AUTOSAR XML (schema 4-0-3)
package /ComponentTypes
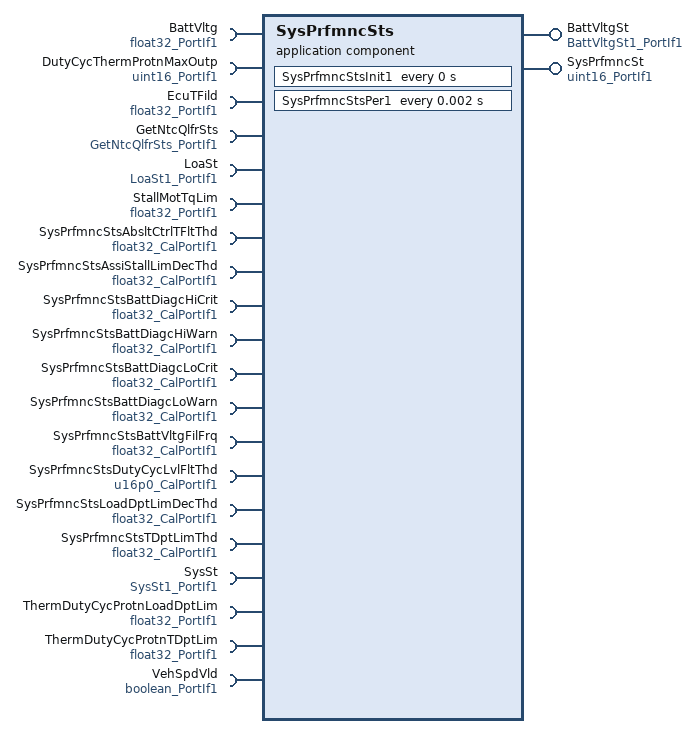
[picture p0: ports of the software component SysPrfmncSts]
  application sw component type SysPrfmncSts
    provide port BattVltgSt: nonqueued-sender-com-spec{data-element=Val, init-value=0}, provided-interface=BattVltgSt1_PortIf1
    provide port SysPrfmncSt: nonqueued-sender-com-spec{data-element=Val, init-value=0}, provided-interface=uint16_PortIf1
    20 x require port:
      BattVltg: nonqueued-receiver-com-spec{data-element=Val, filter=data-filter-type=ALWAYS, init-value=5}, required-interface=float32_PortIf1
      DutyCycThermProtnMaxOutp: nonqueued-receiver-com-spec{data-element=Val, filter=data-filter-type=ALWAYS, init-value=0}, required-interface=uint16_PortIf1
      EcuTFild: nonqueued-receiver-com-spec{data-element=Val, filter=data-filter-type=ALWAYS, init-value=25}, required-interface=float32_PortIf1
      GetNtcQlfrSts: client-com-spec=Oper, required-interface=GetNtcQlfrSts_PortIf1
      LoaSt: nonqueued-receiver-com-spec{data-element=Val, filter=data-filter-type=ALWAYS, init-value=0}, required-interface=LoaSt1_PortIf1
      StallMotTqLim: nonqueued-receiver-com-spec{data-element=Val, filter=data-filter-type=ALWAYS, init-value=8.8}, required-interface=float32_PortIf1
      SysPrfmncStsAbsltCtrlTFltThd: parameter-require-com-spec{init-value=91, parameter=Val}, required-interface=float32_CalPortIf1
      SysPrfmncStsAssiStallLimDecThd: parameter-require-com-spec{init-value=8.8, parameter=Val}, required-interface=float32_CalPortIf1
      SysPrfmncStsBattDiagcHiCrit: parameter-require-com-spec{init-value=18, parameter=Val}, required-interface=float32_CalPortIf1
      SysPrfmncStsBattDiagcHiWarn: parameter-require-com-spec{init-value=17.5, parameter=Val}, required-interface=float32_CalPortIf1
      SysPrfmncStsBattDiagcLoCrit: parameter-require-com-spec{init-value=9, parameter=Val}, required-interface=float32_CalPortIf1
      SysPrfmncStsBattDiagcLoWarn: parameter-require-com-spec{init-value=11.3, parameter=Val}, required-interface=float32_CalPortIf1
      SysPrfmncStsBattVltgFilFrq: parameter-require-com-spec{init-value=10, parameter=Val}, required-interface=float32_CalPortIf1
      SysPrfmncStsDutyCycLvlFltThd: parameter-require-com-spec{init-value=70, parameter=Val}, required-interface=u16p0_CalPortIf1
      SysPrfmncStsLoadDptLimDecThd: parameter-require-com-spec{init-value=8.8, parameter=Val}, required-interface=float32_CalPortIf1
      SysPrfmncStsTDptLimThd: parameter-require-com-spec{init-value=8.8, parameter=Val}, required-interface=float32_CalPortIf1
      SysSt: nonqueued-receiver-com-spec{data-element=Val, filter=data-filter-type=ALWAYS, init-value=3}, required-interface=SysSt1_PortIf1
      ThermDutyCycProtnLoadDptLim: nonqueued-receiver-com-spec{data-element=Val, filter=data-filter-type=ALWAYS, init-value=8.8}, required-interface=float32_PortIf1
      ThermDutyCycProtnTDptLim: nonqueued-receiver-com-spec{data-element=Val, filter=data-filter-type=ALWAYS, init-value=8.8}, required-interface=float32_PortIf1
      VehSpdVld: nonqueued-receiver-com-spec{data-element=Logl, filter=data-filter-type=ALWAYS, init-value=0}, required-interface=boolean_PortIf1
    behavior SysPrfmncSts_InternalBehavior
      ar-typed-per-instance-memorys:
        data BattVltgLpFil: sw-calibration-access=READ-ONLY, type=FilLpRec1
      timing event SysPrfmncSts_InitEvent: start-on-event=SysPrfmncStsInit1, period=0
      timing event TMT_SysPrfmncStsPer1: start-on-event=SysPrfmncStsPer1, period=0.002
      runnable SysPrfmncStsInit1
      runnable SysPrfmncStsPer1
        data-receive-point-by-arguments:
          9 x access:
            REC_BattVltg_Val: accessed-variable=BattVltg.Val
            REC_DutyCycThermProtnMaxOutp_Val: accessed-variable=DutyCycThermProtnMaxOutp.Val
            REC_EcuTFild_Val: accessed-variable=EcuTFild.Val
            REC_LoaSt_Val: accessed-variable=LoaSt.Val
            REC_StallMotTqLim_Val: accessed-variable=StallMotTqLim.Val
            REC_SysSt_Val: accessed-variable=SysSt.Val
            REC_ThermDutyCycProtnLoadDptLim_Val: accessed-variable=ThermDutyCycProtnLoadDptLim.Val
            REC_ThermDutyCycProtnTDptLim_Val: accessed-variable=ThermDutyCycProtnTDptLim.Val
            REC_VehSpdVld_Logl: accessed-variable=VehSpdVld.Logl
        data-send-points:
          access SEND_BattVltgSt_Val_1: accessed-variable=BattVltgSt.Val
          access SEND_SysPrfmncSt_Val: accessed-variable=SysPrfmncSt.Val
        sync call SC_GetNtcQlfrSts_Oper: operation=GetNtcQlfrSts.Oper, timeout=0
  swc implementation SysPrfmncSts_Implementation: behavior=SysPrfmncSts_InternalBehavior
    code-descriptors:
      code Default: artifact-descriptors=autosar-engineering-object={short-label=Default, category=SWSRC}
